AUTOSAR XML (schema 3-2-1)
package /slider/slid1_swc
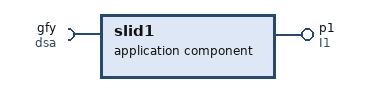
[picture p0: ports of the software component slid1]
  application software component type slid1
    provide port p1: unqueued-provider-com-spec{data-element=gyf, alive-timeout=60.0}, provided-interface=I1
    require port gfy: unqueued-provider-com-spec{data-element=sdds, alive-timeout=60.0}, provided-interface=dsa
  internal behavior slid1Behavior: compontent=slid1
    timing event fds: start-on-event=tsy, period=0.0
    runnable tsy: can-be-invoked-concurrently=true
      data write access gdsa: data-element=p1.gyf
  swc implementation slid1Implementation: behavior=slid1Behavior
